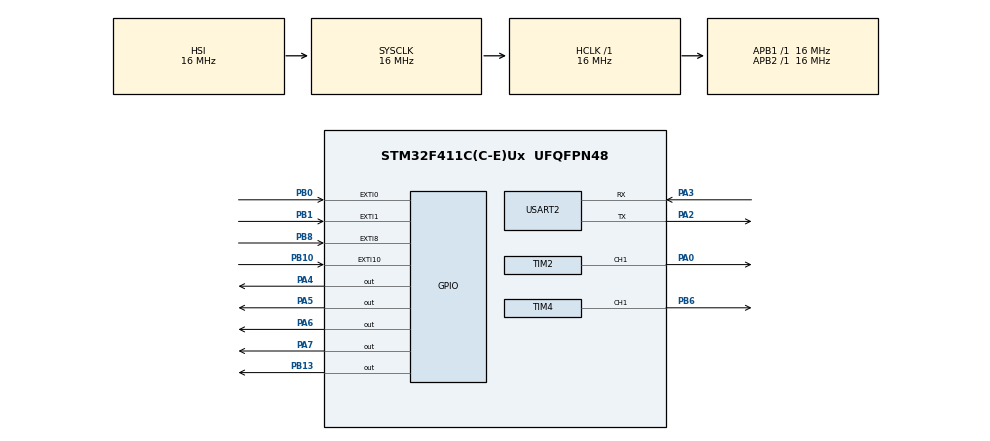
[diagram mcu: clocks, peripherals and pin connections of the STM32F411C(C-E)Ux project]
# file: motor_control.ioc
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Mcu.Family=STM32F4
Mcu.Name=STM32F411C(C-E)Ux
Mcu.Package=UFQFPN48
NVIC.EXTI0_IRQn=true\:0\:0\:false\:false\:true\:true\:true\:true
NVIC.EXTI15_10_IRQn=true\:0\:0\:false\:false\:true\:true\:true\:true
NVIC.EXTI1_IRQn=true\:0\:0\:false\:false\:true\:true\:true\:true
NVIC.EXTI9_5_IRQn=true\:0\:0\:false\:false\:true\:true\:true\:true
NVIC.PriorityGroup=NVIC_PRIORITYGROUP_4
PA0-WKUP.Signal=S_TIM2_CH1_ETR
PA2.Mode=Asynchronous
PA2.Signal=USART2_TX
PA3.Mode=Asynchronous
PA3.Signal=USART2_RX
PA4.Signal=GPIO_Output
PA5.Signal=GPIO_Output
PA6.Signal=GPIO_Output
PA7.Signal=GPIO_Output
PB0.Signal=GPXTI0
PB1.Signal=GPXTI1
PB10.Signal=GPXTI10
PB13.Signal=GPIO_Output
PB6.Signal=S_TIM4_CH1
PB8.Signal=GPXTI8
ProjectManager.HeapSize=0x200
ProjectManager.StackSize=0x400
ProjectManager.TargetToolchain=STM32CubeIDE
RCC.AHBFreq_Value=16000000
RCC.APB1Freq_Value=16000000
RCC.APB2Freq_Value=16000000
RCC.CortexFreq_Value=16000000
RCC.HSE_VALUE=25000000
RCC.HSI_VALUE=16000000
RCC.LSE_VALUE=32768
RCC.SYSCLKFreq_VALUE=16000000
RCC.VCOOutputFreq_Value=192000000
SH.S_TIM2_CH1_ETR.0=TIM2_CH1,PWM Generation1 CH1
SH.S_TIM4_CH1.0=TIM4_CH1,PWM Generation1 CH1
TIM2.Channel-PWM\ Generation1\ CH1=TIM_CHANNEL_1
TIM4.Channel-PWM\ Generation1\ CH1=TIM_CHANNEL_1
USART2.VirtualMode=VM_ASYNC
board=custom

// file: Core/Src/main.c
/* USER CODE BEGIN Header */
/**
  ******************************************************************************
  * @file           : main.c
  * @brief          : Main program body
  ******************************************************************************
  * @attention
  *
  * Copyright (c) 2025 STMicroelectronics.
  * All rights reserved.
  *
  * This software is licensed under terms that can be found in the LICENSE file
  * in the root directory of this software component.
  * If no LICENSE file comes with this software, it is provided AS-IS.
  *
  ******************************************************************************
  */
#include "motor.h"
/* USER CODE END Header */
#include "main.h"

TIM_HandleTypeDef htim2;
TIM_HandleTypeDef htim4;

UART_HandleTypeDef huart2;

void SystemClock_Config(void);
static void MX_GPIO_Init(void);
static void MX_TIM2_Init(void);
static void MX_USART2_UART_Init(void);
static void MX_TIM4_Init(void);

int main(void)
{

  /* MCU Configuration--------------------------------------------------------*/

  /* Reset of all peripherals, Initializes the Flash interface and the Systick. */
  HAL_Init();

  /* Configure the system clock */
  SystemClock_Config();

  /* Initialize all configured peripherals */
  MX_GPIO_Init();
  MX_TIM2_Init();
  MX_USART2_UART_Init();
  MX_TIM4_Init();
  /* USER CODE BEGIN 2 */
  motor_init();

  /* USER CODE END 2 */

  /* Infinite loop */
  /* USER CODE BEGIN WHILE */
  while (1)
  {
	  handle_serial_input();
	  process_command();
	  // 1. Calculate RPM for each motor from encoder counts
	  calculate_rpm(&left_motor);
	  calculate_rpm(&right_motor);

	  // 2. Run PID update to get new PWM values
	  int left_pwm = motor_update_pid(&left_motor);
	  int right_pwm = motor_update_pid(&right_motor);

	  // 3. Determine direction based on target RPM sign (assuming positive RPM means forward)
	  uint8_t left_dir = (left_motor.target_rpm > 0) ? 1 : 2;
	  uint8_t right_dir = (right_motor.target_rpm > 0) ? 1 : 2;

	  // 4. Apply new PWM and direction to motors
	  motor_set(&left_motor, left_dir, left_pwm);
	  motor_set(&right_motor, right_dir, right_pwm);

	  // 5. Optional: Add small delay or use a timer for consistent control loop timing
	  HAL_Delay(10);  // 10 ms delay ~ 100 Hz control loop frequency

	  // 6. Optional: UART debug prints for RPM and PWM values (commented out)
	  /*
	  printf("Left RPM: %d, PWM: %d\r\n", left_motor.current_rpm, left_pwm);
	  printf("Right RPM: %d, PWM: %d\r\n", right_motor.current_rpm, right_pwm);
	  */
    /* USER CODE END WHILE */

  }
}

void SystemClock_Config(void)
{
  RCC_OscInitTypeDef RCC_OscInitStruct = {0};
  RCC_ClkInitTypeDef RCC_ClkInitStruct = {0};

  /** Configure the main internal regulator output voltage
  */
  __HAL_RCC_PWR_CLK_ENABLE();
  __HAL_PWR_VOLTAGESCALING_CONFIG(PWR_REGULATOR_VOLTAGE_SCALE1);

  /** Initializes the RCC Oscillators according to the specified parameters
  * in the RCC_OscInitTypeDef structure.
  */
  RCC_OscInitStruct.OscillatorType = RCC_OSCILLATORTYPE_HSI;
  RCC_OscInitStruct.HSIState = RCC_HSI_ON;
  RCC_OscInitStruct.HSICalibrationValue = RCC_HSICALIBRATION_DEFAULT;
  RCC_OscInitStruct.PLL.PLLState = RCC_PLL_NONE;
  if (HAL_RCC_OscConfig(&RCC_OscInitStruct) != HAL_OK)
  {
    Error_Handler();
  }

  /** Initializes the CPU, AHB and APB buses clocks
  */
  RCC_ClkInitStruct.ClockType = RCC_CLOCKTYPE_HCLK|RCC_CLOCKTYPE_SYSCLK
                              |RCC_CLOCKTYPE_PCLK1|RCC_CLOCKTYPE_PCLK2;
  RCC_ClkInitStruct.SYSCLKSource = RCC_SYSCLKSOURCE_HSI;
  RCC_ClkInitStruct.AHBCLKDivider = RCC_SYSCLK_DIV1;
  RCC_ClkInitStruct.APB1CLKDivider = RCC_HCLK_DIV1;
  RCC_ClkInitStruct.APB2CLKDivider = RCC_HCLK_DIV1;

  if (HAL_RCC_ClockConfig(&RCC_ClkInitStruct, FLASH_LATENCY_0) != HAL_OK)
  {
    Error_Handler();
  }
}

static void MX_TIM2_Init(void)
{

  TIM_MasterConfigTypeDef sMasterConfig = {0};
  TIM_OC_InitTypeDef sConfigOC = {0};

  htim2.Instance = TIM2;
  htim2.Init.Prescaler = 0;
  htim2.Init.CounterMode = TIM_COUNTERMODE_UP;
  htim2.Init.Period = 4294967295;
  htim2.Init.ClockDivision = TIM_CLOCKDIVISION_DIV1;
  htim2.Init.AutoReloadPreload = TIM_AUTORELOAD_PRELOAD_DISABLE;
  if (HAL_TIM_PWM_Init(&htim2) != HAL_OK)
  {
    Error_Handler();
  }
  sMasterConfig.MasterOutputTrigger = TIM_TRGO_RESET;
  sMasterConfig.MasterSlaveMode = TIM_MASTERSLAVEMODE_DISABLE;
  if (HAL_TIMEx_MasterConfigSynchronization(&htim2, &sMasterConfig) != HAL_OK)
  {
    Error_Handler();
  }
  sConfigOC.OCMode = TIM_OCMODE_PWM1;
  sConfigOC.Pulse = 0;
  sConfigOC.OCPolarity = TIM_OCPOLARITY_HIGH;
  sConfigOC.OCFastMode = TIM_OCFAST_DISABLE;
  if (HAL_TIM_PWM_ConfigChannel(&htim2, &sConfigOC, TIM_CHANNEL_1) != HAL_OK)
  {
    Error_Handler();
  }
  HAL_TIM_MspPostInit(&htim2);

}

static void MX_TIM4_Init(void)
{

  TIM_MasterConfigTypeDef sMasterConfig = {0};
  TIM_OC_InitTypeDef sConfigOC = {0};

  htim4.Instance = TIM4;
  htim4.Init.Prescaler = 0;
  htim4.Init.CounterMode = TIM_COUNTERMODE_UP;
  htim4.Init.Period = 65535;
  htim4.Init.ClockDivision = TIM_CLOCKDIVISION_DIV1;
  htim4.Init.AutoReloadPreload = TIM_AUTORELOAD_PRELOAD_DISABLE;
  if (HAL_TIM_PWM_Init(&htim4) != HAL_OK)
  {
    Error_Handler();
  }
  sMasterConfig.MasterOutputTrigger = TIM_TRGO_RESET;
  sMasterConfig.MasterSlaveMode = TIM_MASTERSLAVEMODE_DISABLE;
  if (HAL_TIMEx_MasterConfigSynchronization(&htim4, &sMasterConfig) != HAL_OK)
  {
    Error_Handler();
  }
  sConfigOC.OCMode = TIM_OCMODE_PWM1;
  sConfigOC.Pulse = 0;
  sConfigOC.OCPolarity = TIM_OCPOLARITY_HIGH;
  sConfigOC.OCFastMode = TIM_OCFAST_DISABLE;
  if (HAL_TIM_PWM_ConfigChannel(&htim4, &sConfigOC, TIM_CHANNEL_1) != HAL_OK)
  {
    Error_Handler();
  }
  HAL_TIM_MspPostInit(&htim4);

}

static void MX_USART2_UART_Init(void)
{

  huart2.Instance = USART2;
  huart2.Init.BaudRate = 115200;
  huart2.Init.WordLength = UART_WORDLENGTH_8B;
  huart2.Init.StopBits = UART_STOPBITS_1;
  huart2.Init.Parity = UART_PARITY_NONE;
  huart2.Init.Mode = UART_MODE_TX_RX;
  huart2.Init.HwFlowCtl = UART_HWCONTROL_NONE;
  huart2.Init.OverSampling = UART_OVERSAMPLING_16;
  if (HAL_UART_Init(&huart2) != HAL_OK)
  {
    Error_Handler();
  }

}

static void MX_GPIO_Init(void)
{
  GPIO_InitTypeDef GPIO_InitStruct = {0};

  /* GPIO Ports Clock Enable */
  __HAL_RCC_GPIOA_CLK_ENABLE();
  __HAL_RCC_GPIOB_CLK_ENABLE();

  /*Configure GPIO pin Output Level */
  HAL_GPIO_WritePin(GPIOA, GPIO_PIN_4|GPIO_PIN_5|GPIO_PIN_6|GPIO_PIN_7, GPIO_PIN_RESET);

  /*Configure GPIO pin Output Level */
  HAL_GPIO_WritePin(GPIOB, GPIO_PIN_13, GPIO_PIN_RESET);

  /*Configure GPIO pins : PA4 PA5 PA6 PA7 */
  GPIO_InitStruct.Pin = GPIO_PIN_4|GPIO_PIN_5|GPIO_PIN_6|GPIO_PIN_7;
  GPIO_InitStruct.Mode = GPIO_MODE_OUTPUT_PP;
  GPIO_InitStruct.Pull = GPIO_NOPULL;
  GPIO_InitStruct.Speed = GPIO_SPEED_FREQ_LOW;
  HAL_GPIO_Init(GPIOA, &GPIO_InitStruct);

  /*Configure GPIO pins : PB0 PB1 PB10 PB8 */
  GPIO_InitStruct.Pin = GPIO_PIN_0|GPIO_PIN_1|GPIO_PIN_10|GPIO_PIN_8;
  GPIO_InitStruct.Mode = GPIO_MODE_IT_RISING;
  GPIO_InitStruct.Pull = GPIO_NOPULL;
  HAL_GPIO_Init(GPIOB, &GPIO_InitStruct);

  /*Configure GPIO pin : PB13 */
  GPIO_InitStruct.Pin = GPIO_PIN_13;
  GPIO_InitStruct.Mode = GPIO_MODE_OUTPUT_PP;
  GPIO_InitStruct.Pull = GPIO_NOPULL;
  GPIO_InitStruct.Speed = GPIO_SPEED_FREQ_LOW;
  HAL_GPIO_Init(GPIOB, &GPIO_InitStruct);

  /* EXTI interrupt init*/
  HAL_NVIC_SetPriority(EXTI0_IRQn, 0, 0);
  HAL_NVIC_EnableIRQ(EXTI0_IRQn);

  HAL_NVIC_SetPriority(EXTI1_IRQn, 0, 0);
  HAL_NVIC_EnableIRQ(EXTI1_IRQn);

  HAL_NVIC_SetPriority(EXTI9_5_IRQn, 0, 0);
  HAL_NVIC_EnableIRQ(EXTI9_5_IRQn);

  HAL_NVIC_SetPriority(EXTI15_10_IRQn, 0, 0);
  HAL_NVIC_EnableIRQ(EXTI15_10_IRQn);

}

void Error_Handler(void)
{
  __disable_irq();
  while (1)
  {
  }
}
